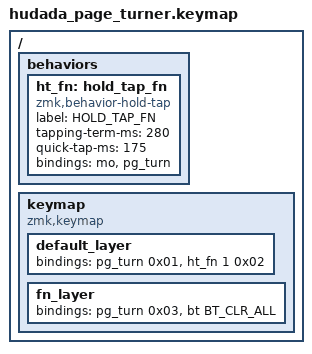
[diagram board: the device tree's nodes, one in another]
// 文件路径: config/hudada_page_turner.keymap

#include <behaviors.dtsi>
#include <dt-bindings/zmk/keys.h>
#include <dt-bindings/zmk/bt.h>
#include "page_turner.dtsi"

/ {
    behaviors {
        // 定义一个 hold-tap 行为
        // tapping-term-ms: 按下多长时间被判定为“长按” (280毫秒)
        // quick-tap-ms: 在长按触发后，如果快速松开再按下，依然算单击
        ht_fn: hold_tap_fn {
            compatible = "zmk,behavior-hold-tap";
            label = "HOLD_TAP_FN";
            #binding-cells = <2>;
            tapping-term-ms = <280>;
            quick-tap-ms = <175>;
            bindings = <&mo>, <&pg_turn>; // 长按: &mo (切换层), 单击: &pg_turn
        };
    };

    keymap {
        compatible = "zmk,keymap";

        // 第0层：默认层
        default_layer {
            // 按键0: 上翻页
            // 按键1: 单击是下翻页, 长按切换到第1层(fn_layer)
            bindings = <
                &pg_turn 0x01      &ht_fn 1 0x02
            >;
        };

        // 第1层：功能层
        fn_layer {
            // 按键0: 返回
            // 按键1: 清除所有蓝牙配对
            bindings = <
                &pg_turn 0x03      &bt BT_CLR_ALL
            >;
        };
    };
};
